# RP2350 register map
Vendor: Raspberry Pi; Series: RP; File version: 0.1
CPU: CM33 r1p0, little endian, MPU, FPU, DSP, VTOR, 4 interrupt priority bits, 52 interrupts, 8 SAU regions
Registers are 32-bit, read-write, reset 0x0 unless marked. A register's access mark holds for its fields unless they carry their own. Offsets are from the block's base; [hi:lo] are bit positions; {n}, {i} and the like mark numbered series; 'fields as' and 'values as' point back to an identical list.

## OTP — SNPS OTP control IF (SBPI and RPi wrapper control)
Base 0x40120000
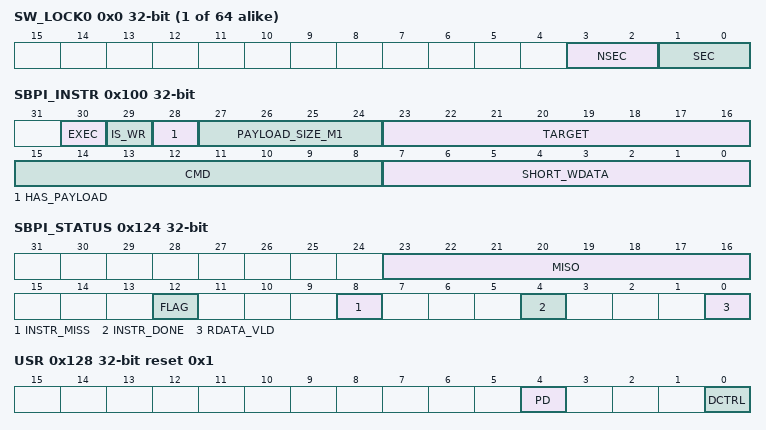
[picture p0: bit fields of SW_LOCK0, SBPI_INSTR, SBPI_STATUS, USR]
{0x0+4i} SW_LOCK{i} (i=0..63) — Software lock register for page {i}. Locks are initialised from the OTP lock pages at reset. This register can be written to further advance the lock state of each page (until next reset), and read to check the current lock state of a page.
  [3:2] NSEC — Non-secure lock status. Writes are OR'd with the current value.
    0=read_write; 1=read_only; 3=inaccessible
  [1:0] SEC — Secure lock status. Writes are OR'd with the current value. This field is read-only to Non-secure code.
    0=read_write; 1=read_only; 3=inaccessible
0x100 SBPI_INSTR — Dispatch instructions to the SBPI interface, used for programming the OTP fuses.
  [30] EXEC wo — Execute instruction
  [29] IS_WR — Payload type is write
  [28] HAS_PAYLOAD — Instruction has payload (data to be written or to be read)
  [27:24] PAYLOAD_SIZE_M1 — Instruction payload size in bytes minus 1
  [23:16] TARGET — Instruction target, it can be PMC (0x3a) or DAP (0x02)
  [15:8] CMD — Pre-defined description
  [7:0] SHORT_WDATA — wdata to be used only when payload_size_m1=0
0x104 SBPI_WDATA_0 — SBPI write payload bytes 3..0
  [31:0] SBPI_WDATA_0 — Pre-defined description
0x108 SBPI_WDATA_1 — SBPI write payload bytes 7..4
  [31:0] SBPI_WDATA_1 — Pre-defined description
0x10C SBPI_WDATA_2 — SBPI write payload bytes 11..8
  [31:0] SBPI_WDATA_2 — Pre-defined description
0x110 SBPI_WDATA_3 — SBPI write payload bytes 15..12
  [31:0] SBPI_WDATA_3 — Pre-defined description
0x114 SBPI_RDATA_0 — Read payload bytes 3..0. Once read, the data in the register will automatically clear to 0.
  [31:0] SBPI_RDATA_0 ro read-modifies — Pre-defined description
0x118 SBPI_RDATA_1 — Read payload bytes 7..4. Once read, the data in the register will automatically clear to 0.
  [31:0] SBPI_RDATA_1 ro read-modifies — Pre-defined description
0x11C SBPI_RDATA_2 — Read payload bytes 11..8. Once read, the data in the register will automatically clear to 0.
  [31:0] SBPI_RDATA_2 ro read-modifies — Pre-defined description
0x120 SBPI_RDATA_3 — Read payload bytes 15..12. Once read, the data in the register will automatically clear to 0.
  [31:0] SBPI_RDATA_3 ro read-modifies — Pre-defined description
0x124 SBPI_STATUS — register description
  [23:16] MISO ro — SBPI MISO (master in - slave out): response from SBPI
  [12] FLAG ro — SBPI flag
  [8] INSTR_MISS write-1-clears — Last instruction missed (dropped), as the previous has not finished running
  [4] INSTR_DONE write-1-clears — Last instruction done
  [0] RDATA_VLD write-1-clears — Read command has returned data
0x128 USR reset 0x1 — Controls for APB data read interface (USER interface)
  [4] PD — Power-down; 1 disables current reference. Must be 0 to read data from the OTP.
  [0] DCTRL — 1 enables USER interface; 0 disables USER interface (enables SBPI). This bit must be cleared before performing any SBPI access, such as when programming the OTP. The APB data read interface (USER interface) will be inaccessible during this time, and will return a bus error if any read is attempted.
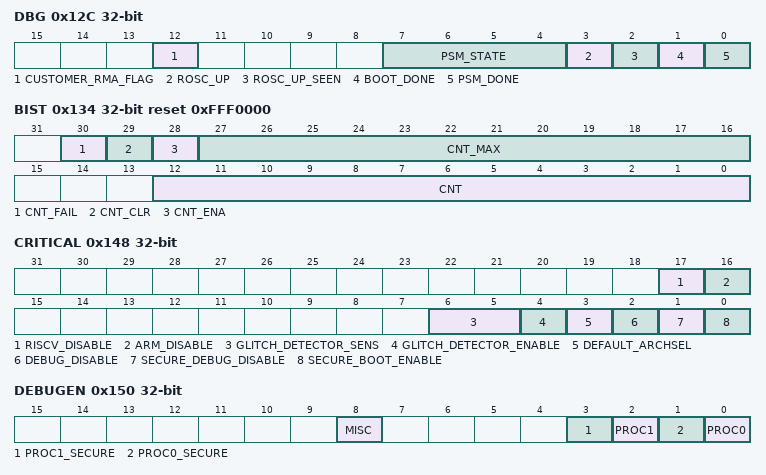
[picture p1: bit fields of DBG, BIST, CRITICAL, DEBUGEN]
0x12C DBG — Debug for OTP power-on state machine
  [12] CUSTOMER_RMA_FLAG ro — The chip is in RMA mode
  [7:4] PSM_STATE ro — Monitor the PSM FSM's state
  [3] ROSC_UP ro — Ring oscillator is up and running
  [2] ROSC_UP_SEEN write-1-clears — Ring oscillator was seen up and running
  [1] BOOT_DONE ro — PSM boot done status flag
  [0] PSM_DONE ro — PSM done status flag
0x134 BIST reset 0xFFF0000 — During BIST, count address locations that have at least one leaky bit
  [30] CNT_FAIL ro — Flag if the count of address locations with at least one leaky bit exceeds cnt_max
  [29] CNT_CLR wo — Clear counter before use
  [28] CNT_ENA — Enable the counter before the BIST function is initiated
  [27:16] CNT_MAX — The cnt_fail flag will be set if the number of leaky locations exceeds this number
  [12:0] CNT ro — Number of locations that have at least one leaky bit. Note: This count is true only if the BIST was initiated without the fix option.
0x138 CRT_KEY_W0 — Word 0 (bits 31..0) of the key. Write only, read returns 0x0
  [31:0] CRT_KEY_W0 wo — Pre-defined description
0x13C CRT_KEY_W1 — Word 1 (bits 63..32) of the key. Write only, read returns 0x0
  [31:0] CRT_KEY_W1 wo — Pre-defined description
0x140 CRT_KEY_W2 — Word 2 (bits 95..64) of the key. Write only, read returns 0x0
  [31:0] CRT_KEY_W2 wo — Pre-defined description
0x144 CRT_KEY_W3 — Word 3 (bits 127..96) of the key. Write only, read returns 0x0
  [31:0] CRT_KEY_W3 wo — Pre-defined description
0x148 CRITICAL — Quickly check values of critical flags read during boot up
  [17] RISCV_DISABLE ro — Pre-defined description
  [16] ARM_DISABLE ro — Pre-defined description
  [6:5] GLITCH_DETECTOR_SENS ro — Pre-defined description
  [4] GLITCH_DETECTOR_ENABLE ro — Pre-defined description
  [3] DEFAULT_ARCHSEL ro — Pre-defined description
  [2] DEBUG_DISABLE ro — Pre-defined description
  [1] SECURE_DEBUG_DISABLE ro — Pre-defined description
  [0] SECURE_BOOT_ENABLE ro — Pre-defined description
0x14C KEY_VALID — Which keys were valid (enrolled) at boot time
  [7:0] KEY_VALID ro — Pre-defined description
0x150 DEBUGEN — Enable a debug feature that has been disabled. Debug features are disabled if one of the relevant critical boot flags is set in OTP (DEBUG_DISABLE or SECURE_DEBUG_DISABLE), OR if a debug key is marked valid in OTP, and the matching key value has not been supplied over SWD. Specifically: - The DEBUG_DISABLE flag disables all debug features. This can be fully overridden by setting all bits of this register. - The SECURE_DEBUG_DISABLE flag disables secure processor debug. This can be fully overridden by setting the PROC0_SECURE and PROC1_SECURE bits of this register. - If a single debug key has been registered, and no matching key value has been supplied over SWD, then all debug features are disabled. This can be fully overridden by setting all bits of this register. - If both debug keys have been registered, and the Non-secure key's value (key 6) has been supplied over SWD, secure processor debug is disabled. This can be fully overridden by setting the PROC0_SECURE and PROC1_SECURE bits of this register. - If both debug keys have been registered, and the Secure key's value (key 5) has been supplied over SWD, then no debug features are disabled by the key mechanism. However, note that in this case debug features may still be disabled by the critical boot flags.
  [8] MISC — Enable other debug components. Specifically, the CTI, and the APB-AP used to access the RISC-V Debug Module. These components are disabled by default if either of the debug disable critical flags is set, or if at least one debug key has been enrolled and the least secure of these enrolled key values has not been provided over SWD.
  [3] PROC1_SECURE — Permit core 1's Mem-AP to generate Secure accesses, assuming it is enabled at all. Also enable secure debug of core 1 (SPIDEN and SPNIDEN). Secure debug of core 1 is disabled by default if the secure debug disable critical flag is set, or if at least one debug key has been enrolled and the most secure of these enrolled key values not yet provided over SWD.
  [2] PROC1 — Enable core 1's Mem-AP if it is currently disabled. The Mem-AP is disabled by default if either of the debug disable critical flags is set, or if at least one debug key has been enrolled and the least secure of these enrolled key values has not been provided over SWD.
  [1] PROC0_SECURE — Permit core 0's Mem-AP to generate Secure accesses, assuming it is enabled at all. Also enable secure debug of core 0 (SPIDEN and SPNIDEN). Secure debug of core 0 is disabled by default if the secure debug disable critical flag is set, or if at least one debug key has been enrolled and the most secure of these enrolled key values not yet provided over SWD. Note also that core Mem-APs are unconditionally disabled when a core is switched to RISC-V mode (by setting the ARCHSEL bit and performing a warm reset of the core).
  [0] PROC0 — Enable core 0's Mem-AP if it is currently disabled. The Mem-AP is disabled by default if either of the debug disable critical flags is set, or if at least one debug key has been enrolled and the least secure of these enrolled key values has not been provided over SWD. Note also that core Mem-APs are unconditionally disabled when a core is switched to RISC-V mode (by setting the ARCHSEL bit and performing a warm reset of the core).
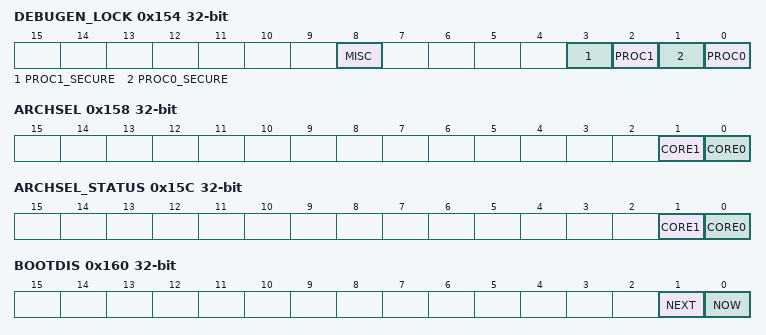
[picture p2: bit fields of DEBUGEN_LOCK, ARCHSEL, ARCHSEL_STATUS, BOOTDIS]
0x154 DEBUGEN_LOCK — Write 1s to lock corresponding bits in DEBUGEN. This register is reset by the processor cold reset.
  [8] MISC — Write 1 to lock the MISC bit of DEBUGEN. Can't be cleared once set.
  [3] PROC1_SECURE — Write 1 to lock the PROC1_SECURE bit of DEBUGEN. Can't be cleared once set.
  [2] PROC1 — Write 1 to lock the PROC1 bit of DEBUGEN. Can't be cleared once set.
  [1] PROC0_SECURE — Write 1 to lock the PROC0_SECURE bit of DEBUGEN. Can't be cleared once set.
  [0] PROC0 — Write 1 to lock the PROC0 bit of DEBUGEN. Can't be cleared once set.
0x158 ARCHSEL — Architecture select (Arm/RISC-V). The default and allowable values of this register are constrained by the critical boot flags. This register is reset by the earliest reset in the switched core power domain (before a processor cold reset). Cores sample their architecture select signal on a warm reset. The source of the warm reset could be the system power-up state machine, the watchdog timer, Arm SYSRESETREQ or from RISC-V hartresetreq. Note that when an Arm core is deselected, its cold reset domain is also held in reset, since in particular the SYSRESETREQ bit becomes inaccessible once the core is deselected. Note also the RISC-V cores do not have a cold reset domain, since their corresponding controls are located in the Debug Module.
  [1] CORE1 — Select architecture for core 1.
    0=arm (Switch core 1 to Arm (Cortex-M33)); 1=riscv (Switch core 1 to RISC-V (Hazard3))
  [0] CORE0 — Select architecture for core 0.
    0=arm (Switch core 0 to Arm (Cortex-M33)); 1=riscv (Switch core 0 to RISC-V (Hazard3))
0x15C ARCHSEL_STATUS — Get the current architecture select state of each core. Cores sample the current value of the ARCHSEL register when their warm reset is released, at which point the corresponding bit in this register will also update.
  [1] CORE1 ro — Current architecture for core 0. Updated on processor warm reset.
    0=arm (Core 1 is currently Arm (Cortex-M33)); 1=riscv (Core 1 is currently RISC-V (Hazard3))
  [0] CORE0 ro — Current architecture for core 0. Updated on processor warm reset.
    0=arm (Core 0 is currently Arm (Cortex-M33)); 1=riscv (Core 0 is currently RISC-V (Hazard3))
0x160 BOOTDIS — Tell the bootrom to ignore scratch register boot vectors (both power manager and watchdog) on the next power up. If an early boot stage has soft-locked some OTP pages in order to protect their contents from later stages, there is a risk that Secure code running at a later stage can unlock the pages by performing a watchdog reset that resets the OTP. This register can be used to ensure that the bootloader runs as normal on the next power up, preventing Secure code at a later stage from accessing OTP in its unlocked state. Should be used in conjunction with the power manager BOOTDIS register.
  [1] NEXT — This flag always ORs writes into its current contents. It can be set but not cleared by software. The BOOTDIS_NEXT bit is OR'd into the BOOTDIS_NOW bit when the core is powered down. Simultaneously, the BOOTDIS_NEXT bit is cleared. Setting this bit means that the boot scratch registers will be ignored following the next core power down. This flag should be set by an early boot stage that has soft-locked OTP pages, to prevent later stages from unlocking it via watchdog reset.
  [0] NOW write-1-clears — When the core is powered down, the current value of BOOTDIS_NEXT is OR'd into BOOTDIS_NOW, and BOOTDIS_NEXT is cleared. The bootrom checks this flag before reading the boot scratch registers. If it is set, the bootrom clears it, and ignores the BOOT registers. This prevents Secure software from diverting the boot path before a bootloader has had the chance to soft lock OTP pages containing sensitive data.
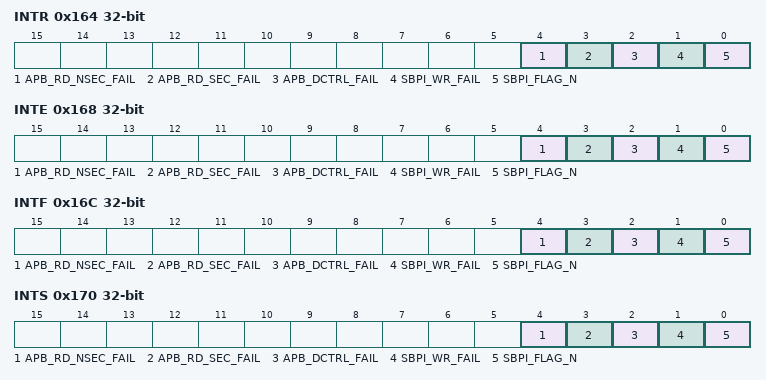
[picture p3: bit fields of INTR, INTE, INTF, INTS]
0x164 INTR — Raw Interrupts
  [4] APB_RD_NSEC_FAIL write-1-clears — Pre-defined description
  [3] APB_RD_SEC_FAIL write-1-clears — Pre-defined description
  [2] APB_DCTRL_FAIL write-1-clears — Pre-defined description
  [1] SBPI_WR_FAIL write-1-clears — Pre-defined description
  [0] SBPI_FLAG_N ro — Pre-defined description
0x168 INTE — Interrupt Enable
  [4] APB_RD_NSEC_FAIL — Pre-defined description
  [3] APB_RD_SEC_FAIL — Pre-defined description
  [2] APB_DCTRL_FAIL — Pre-defined description
  [1] SBPI_WR_FAIL — Pre-defined description
  [0] SBPI_FLAG_N — Pre-defined description
0x16C INTF — Interrupt Force
  fields as INTE
0x170 INTS — Interrupt status after masking & forcing
  [4] APB_RD_NSEC_FAIL ro — Pre-defined description
  [3] APB_RD_SEC_FAIL ro — Pre-defined description
  [2] APB_DCTRL_FAIL ro — Pre-defined description
  [1] SBPI_WR_FAIL ro — Pre-defined description
  [0] SBPI_FLAG_N ro — Pre-defined description
